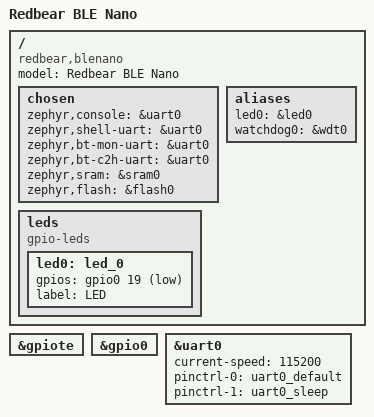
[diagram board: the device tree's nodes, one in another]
/*
 * Copyright (c) 2017 Linaro Limited
 *
 * SPDX-License-Identifier: Apache-2.0
 */

/dts-v1/;
#include <nordic/nrf51822_qfaa.dtsi>
#include "nrf51_blenano-pinctrl.dtsi"

/ {
	model = "Redbear BLE Nano";
	compatible = "redbear,blenano";

	chosen {
		zephyr,console = &uart0;
		zephyr,shell-uart = &uart0;
		zephyr,bt-mon-uart = &uart0;
		zephyr,bt-c2h-uart = &uart0;
		zephyr,sram = &sram0;
		zephyr,flash = &flash0;
	};

	aliases {
		led0 = &led0;
		watchdog0 = &wdt0;
	};

	leds {
		compatible = "gpio-leds";

		led0: led_0 {
			gpios = <&gpio0 19 GPIO_ACTIVE_LOW>;
			label = "LED";
		};
	};
};

&gpiote {
	status = "okay";
};

&gpio0 {
	status = "okay";
};

&uart0 {
	current-speed = <115200>;
	status = "okay";
	pinctrl-0 = <&uart0_default>;
	pinctrl-1 = <&uart0_sleep>;
	pinctrl-names = "default", "sleep";
};
